# STM32H523 register map
File version: 1.3
CPU: CM33 r0p0, little endian, MPU, FPU, 4 interrupt priority bits
Registers are 32-bit, read-write, reset 0x0 unless marked. A register's access mark holds for its fields unless they carry their own. Offsets are from the block's base; [hi:lo] are bit positions; lines under a group give offsets from that group; {n}, {i} and the like mark numbered series; 'fields as' and 'values as' point back to an identical list.

## GPDMA1 — GPDMA register block
Base 0x40020000
Same registers: GPDMA2 0x40021000, GPDMA1_S 0x50020000, GPDMA2_S 0x50021000
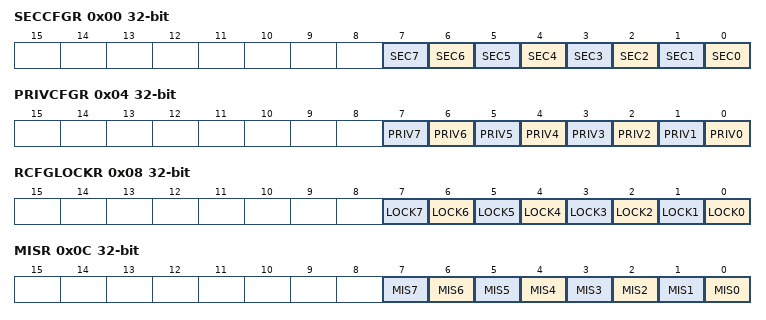
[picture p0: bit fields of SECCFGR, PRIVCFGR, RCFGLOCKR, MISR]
0x00 SECCFGR — GPDMA secure configuration register
  [n] SEC{n} (n=0..7) — secure state of channel x
0x04 PRIVCFGR — GPDMA privileged configuration register
  [n] PRIV{n} (n=0..7) — privileged state of channel x
    0=Unprivileged (Channel is unprivileged); 1=Privileged (Channel is privileged)
0x08 RCFGLOCKR — GPDMA configuration lock register
  [n] LOCK{n} (n=0..7) — lock the configuration of GPDMA_SECCFGR.
0x0C MISR ro — GPDMA nonsecure masked interrupt status register
  [n] MIS{n} (n=0..7) — masked interrupt status of channel x
    0=NoTrigger (No interrupt has occurred on channel); 1=Trigger (An interrupt has occurred on channel)
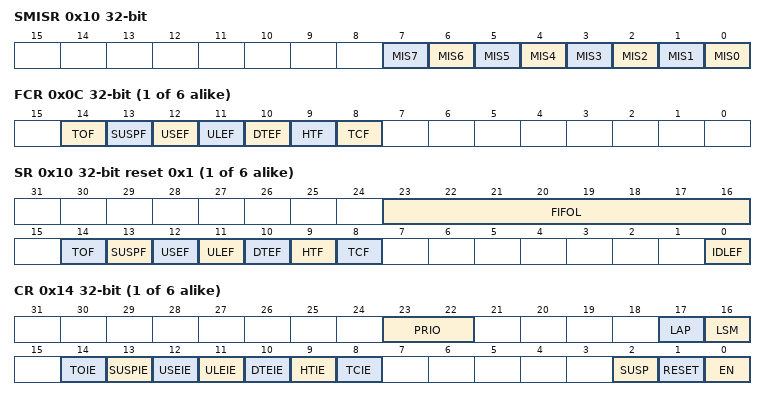
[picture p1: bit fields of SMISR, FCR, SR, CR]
0x10 SMISR ro — GPDMA secure masked interrupt status register
  [n] MIS{n} (n=0..7) — masked interrupt status of the secure channel x
{0x50+0x80*i} CH{i} (i=0..5) group — Channel cluster
  0x00 LBAR — GPDMA channel 0 linked-list base address register
    [31:16] LBA — linked-list base address of GPDMA channel x
  0x0C FCR wo — GPDMA channel 0 flag clear register
    [all] fields
      1=Clear flag
    [14] TOF — trigger overrun flag clear
    [13] SUSPF — completed suspension flag clear
    [12] USEF — user setting error flag clear
    [11] ULEF — update link transfer error flag clear
    [10] DTEF — data transfer error flag clear
    [9] HTF — half transfer flag clear
    [8] TCF — transfer complete flag clear
  0x10 SR ro reset 0x1 — GPDMA channel 0 status register
    [23:16] FIFOL — monitored FIFO level
    [14] TOF — trigger overrun flag
      0=NoTrigger (Event not triggered); 1=Trigger (Event triggered)
    [13] SUSPF — completed suspension flag
      values as TOF
    [12] USEF — user setting error flag
      values as TOF
    [11] ULEF — update link transfer error flag
      values as TOF
    [10] DTEF — data transfer error flag
      values as TOF
    [9] HTF — half transfer flag
      values as TOF
    [8] TCF — transfer complete flag
      values as TOF
    [0] IDLEF — idle flag
      values as TOF
  0x14 CR — GPDMA channel 0 control register
    [23:22] PRIO — priority level of the channel x GPDMA transfer versus others
      0=LowPrioLowWeight (Low priority, low weight); 1=LowPrioMidWeight (Low priority, mid weight); 2=LowPrioHighWeight (Low priority, high weight); 3=High priority
    [17] LAP — linked-list allocated port
      0=Port 0 (AHB) allocated; 1=Port 1 (AHB) allocated
    [16] LSM — Link step mode
      0=FullLinkedList (Channel executed for full linked list); 1=Once (Channel executed once for current linked list)
    [14] TOIE — trigger overrun interrupt enable
      0=Disabled (Interrupt disabled); 1=Enabled (Interrupt enabled)
    [13] SUSPIE — completed suspension interrupt enable
      values as TOIE
    [12] USEIE — user setting error interrupt enable
      values as TOIE
    [11] ULEIE — update link transfer error interrupt enable
      values as TOIE
    [10] DTEIE — data transfer error interrupt enable
      values as TOIE
    [9] HTIE — half transfer complete interrupt enable
      values as TOIE
    [8] TCIE — transfer complete interrupt enable
      values as TOIE
    [2] SUSP — suspend
      0=NotSuspended (Channel operation not suspended); 1=Suspended (Channel operation suspended)
    [1] RESET wo
      1=Reset channel
    [0] EN — enable
      0=Disabled (Channel disabled); 1=Enabled (Channel enabled)
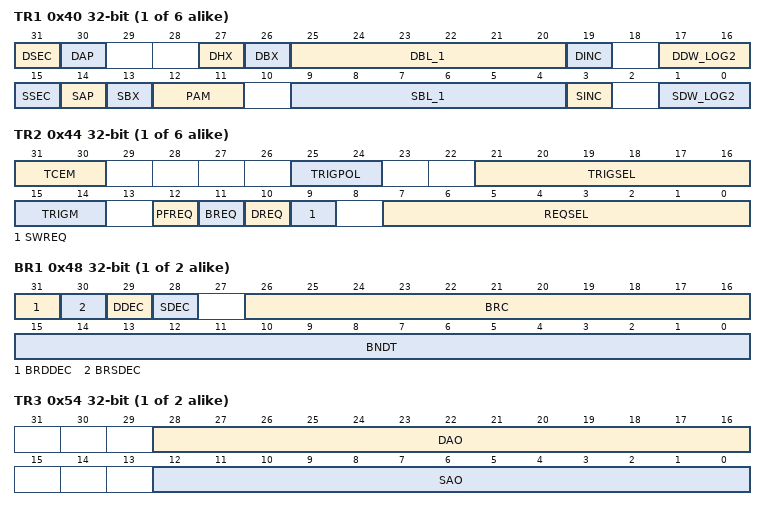
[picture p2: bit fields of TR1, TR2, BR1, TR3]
  0x40 TR1 — GPDMA channel 0 transfer register 1
    [31] DSEC — security attribute of the GPDMA transfer to the destination
    [30] DAP — destination allocated port
      0=Port 0 (AHB) allocated; 1=Port 1 (AHB) allocated
    [27] DHX — destination half-word exchange
      0=NotExchanged (No halfword-based exchange within word); 1=Exchanged (The two consecutive (post PAM) half-words are exchanged in each destination word)
    [26] DBX — destination byte exchange
      0=NotExchanged (No byte-based exchanged within word); 1=Exchanged (The two consecutive (post PAM) bytes are exchanged in each destination half-word)
    [25:20] DBL_1 — destination burst length minus 1, between 0 and 63
    [19] DINC — destination incrementing burst
      0=FixedBurst; 1=Contiguously incremented burst
    [17:16] DDW_LOG2 — binary logarithm of the destination data width of a burst, in bytes
      on read: 0=Byte; 1=Half-word (2 bytes); 2=Word (4 bytes); 3=Error (User setting error) | on write: 0=Byte; 1=Half-word (2 bytes); 2=Word (4 bytes)
    [15] SSEC — security attribute of the GPDMA transfer from the source
    [14] SAP — source allocated port
      0=Port 0 (AHB) allocated; 1=Port 1 (AHB) allocated
    [13] SBX — source byte exchange within the unaligned half-word of each source word
      values as DBX
    [12:11] PAM — padding/alignment mode
    [9:4] SBL_1 — source burst length minus 1, between 0 and 63
    [3] SINC — source incrementing burst
      0=FixedBurst; 1=Contiguously incremented burst
    [1:0] SDW_LOG2 — binary logarithm of the source data width of a burst in bytes
      values as DDW_LOG2
  0x44 TR2 — GPDMA channel 0 transfer register 2
    [31:30] TCEM — transfer complete event mode
      0=BlockLevel (At block level: the complete (and the half) transfer event is generated at the (respectively half of the) end of a block); 2=LliLevel (At LLI level: the complete transfer event is generated at the end of the LLI transfer. The half transfer event is generated at the half of the LLI data transfer); 3=ChannelLevel (At channel level: the complete transfer event is generated at the end of the last LLI transfer. The half transfer event is generated at the half of the data transfer of the last LLI)
    [25:24] TRIGPOL — trigger event polarity
      0=NoTrigger; 1=RisingEdge (Trigger on rising edge); 2=FallingEdge (Trigger on falling edge)
    [21:16] TRIGSEL — trigger event input selection
      {v}=EXTI{v} (exti{v} is trigger input) (v=0..7); 8=TAMP_TRG1 (tamp_trg1 is trigger input); 9=TAMP_TRG2 (tamp_trg2 is trigger input); 11=LPTIM1_CH1 (lptim1_ch1 is trigger input); 12=LPTIM1_CH2 (lptim1_ch2 is trigger input); 13=LPTIM2_CH1 (lptim2_ch1 is trigger input); 14=LPTIM2_CH2 (lptim2_ch2 is trigger input); 15=RTC_ALRA_TRG (rtc_alra_trg is trigger input); 16=RTC_ALRB_TRG (rtc_alrb_trg is trigger input); 17=RTC_WUT_TRG (rtc_wut_trg is trigger input); {v}=GPDMA1_CH{v-18}_TC (gpdma1_ch{v-18}_tc is trigger input) (v=18..25); {v}=GPDMA2_CH{v-26}_TC (gpdma2_ch{v-26}_tc is trigger input) (v=26..33); 34=TIM2_TRG0 (tim2_trgo is trigger input); 44=COMP1_OUT (comp1_out is trigger input)
    [15:14] TRIGM — trigger mode
      0=BlockLevel (At block level: the first burst read of each block transfer is conditioned by one hit trigger); 2=LinkLevel (At link level: a LLI link transfer is conditioned by one hit trigger); 3=ProgrammedBurstLevel (At programmed burst level: programmed burst read is conditioned by one hit trigger.)
    [12] PFREQ — Hardware request in peripheral flow control mode
      0=GpdmaControlMode (The selected hardware request is driven by a peripheral with a hardware request/acknowledge protocol in GPDMA control mode); 1=PeripheralControlMode (The selected hardware request is driven by a peripheral with a hardware request/acknowledge protocol in peripheral control mode.)
    [11] BREQ — Block hardware request
      0=Burst (The selected hardware request is driven by a peripheral with a hardware request/acknowledge protocol at a burst level); 1=Block (The selected hardware request is driven by a peripheral with a hardware request/acknowledge protocol at a block level)
    [10] DREQ — destination hardware request
      0=Source (Selected hardware request driven by a source peripheral); 1=Destination (Selected hardware request driven by a destination peripheral)
    [9] SWREQ — software request
      0=Hardware (No software request. The selected hardware request REQSEL[7:0] is taken into account); 1=Software request for memory-to-memory transfer
    [7:0] REQSEL — GPDMA hardware request selection
      0=ADC1_DMA (adc1_dma selected); 2=DAC1_CH1_DMA (dac1_ch1_dma selected); 3=DAC1_CH2_DMA (dac1_ch2_dma selected); 4=TIM6_UPD_DMA (tim6_upd_dma selected); 5=TIM7_UPD_DMA (tim7_upd_dma selected); 6=SPI1_RX_DMA (spi1_rx_dma selected); 7=SPI1_TX_DMA (spi1_tx_dma selected); 8=SPI2_RX_DMA (spi2_rx_dma selected); 9=SPI2_TX_DMA (spi2_tx_dma selected); 10=SPI3_RX_DMA (spi3_rx_dma selected); 11=SPI3_TX_DMA (spi3_tx_dma selected); 12=I2C1_RX_DMA (i2c1_rx_dma selected); 13=I2C1_TX_DMA (i2c1_tx_dma selected); 15=I2C2_RX_DMA (i2c2_rx_dma selected); 16=I2C2_TX_DMA (i2c2_tx_dma selected); 18=I2C3_RX_DMA (i2c3_rx_dma selected); 19=I2C3_TX_DMA (i2c3_tx_dma selected); 21=USART1_RX_DMA (usart1_rx_dma selected); 22=USART1_TX_DMA (usart1_tx_dma selected); 23=USART2_RX_DMA (usart2_rx_dma selected); 24=USART2_TX_DMA (usart2_tx_dma selected); 25=USART3_RX_DMA (usart3_rx_dma selected); 26=USART3_TX_DMA (usart3_tx_dma selected); 27=UART4_RX_DMA (uart4_rx_dma selected); 28=UART4_TX_DMA (uart4_tx_dma selected); 29=UART5_RX_DMA (uart5_rx_dma selected); 30=UART5_TX_DMA (uart5_tx_dma selected); 31=USART6_RX_DMA (usart6_rx_dma selected); 32=USART6_TX_DMA (usart6_tx_dma selected); 33=UART7_RX_DMA (uart7_rx_dma selected); 34=UART7_TX_DMA (uart7_tx_dma selected); 35=UART8_RX_DMA (uart8_rx_dma selected); 36=UART8_TX_DMA (uart8_tx_dma selected); 37=UART9_RX_DMA (uart9_rx_dma selected); 38=UART9_TX_DMA (uart9_tx_dma selected); 39=UART10_RX_DMA (uart10_rx_dma selected); 40=UART10_TX_DMA (uart10_tx_dma selected); 41=UART11_RX_DMA (uart11_rx_dma selected); 42=UART11_TX_DMA (uart11_tx_dma selected); 43=UART12_RX_DMA (uart12_rx_dma selected); 44=UART12_TX_DMA (uart12_tx_dma selected); 45=LPUART1_RX_DMA (lpuart1_rx_dma selected); 46=LPUART1_TX_DMA (lpuart1_tx_dma selected); 47=SPI4_RX_DMA (spi4_rx_dma selected); 48=SPI4_TX_DMA (spi4_tx_dma selected); 49=SPI5_RX_DMA (spi5_rx_dma selected); 50=SPI5_TX_DMA (spi5_tx_dma selected); 51=SPI6_RX_DMA (spi6_rx_dma selected); 52=SPI6_TX_DMA (spi6_tx_dma selected); 53=SAI1_A_DMA (sai1_a_dma selected); 54=SAI1_B_DMA (sai1_b_dma selected); 55=SAI2_A_DMA (sai2_a_dma selected); 56=SAI2_B_DMA (sai2_b_dma selected); 57=OSPI1_DMA (ospi1_dma selected); {v}=TIM1_CC{v-57}_DMA (tim1_cc{v-57}_dma selected) (v=58..61); 62=TIM1_UPD_DMA (tim1_upd_dma selected); 63=TIM1_TRG_DMA (tim1_trg_dma selected); 64=TIM1_COM_DMA (tim1_com_dma selected); {v}=TIM8_CC{v-64}_DMA (tim8_cc{v-64}_dma selected) (v=65..68); 69=TIM8_UPD_DMA (tim8_upd_dma selected); 70=TIM8_TIG_DMA (tim8_tig_dma selected); 71=TIM8_COM_DMA (tim8_com_dma selected); {v}=TIM2_CC{v-71}_DMA (tim2_cc{v-71}_dma selected) (v=72..75); 76=TIM2_UPD_DMA (tim2_upd_dma selected); {v}=TIM3_CC{v-76}_DMA (tim3_cc{v-76}_dma selected) (v=77..80); 81=TIM3_UPD_DMA (tim3_upd_dma selected); 82=TIM3_TRG_DMA (tim3_trg_dma selected); {v}=TIM4_CC{v-82}_DMA (tim4_cc{v-82}_dma selected) (v=83..86); 87=TIM4_UPD_DMA (tim4_upd_dma selected); {v}=TIM5_CC{v-87}_DMA (tim5_cc{v-87}_dma selected) (v=88..91); 92=TIM5_UPD_DMA (tim5_upd_dma selected); 93=TIM5_TRG_DMA (tim5_trg_dma selected); 94=TIM15_CC1_DMA (tim15_cc1_dma selected); 95=TIM15_UPD_DMA (tim15_upd_dma selected); 96=TIM15_TRG_DMA (tim15_trg_dma selected); 97=TIM15_COM_DMA (tim15_com_dma selected); 98=TIM16_CC1_DMA (tim16_cc1_dma selected); 99=TIM16_UPD_DMA (tim16_upd_dma selected); 100=TIM17_CC1_DMA (tim17_cc1_dma selected); 101=TIM17_UPD_DMA (tim17_upd_dma selected); 102=LPTIM1_IC1_DMA (lptim1_ic1_dma selected); 103=LPTIM1_IC2_DMA (lptim1_ic2_dma selected); 104=LPTIM1_UE_DMA (lptim1_ue_dma selected); 105=LPTIM2_IC1_DMA (lptim2_ic1_dma selected); 106=LPTIM2_IC2_DMA (lptim2_ic2_dma selected); 107=LPTIM2_UE_DMA (lptim2_ue_dma selected); 108=DCMI_PSSI_DMA (dcmi_dma or pssi_dma(1) selected); 109=AES_OUT_DMA (aes_out_dma selected); 110=AES_IN_DMA (aes_in_dma selected); 111=HASH_IN_DMA (hash_in_dma selected); 112=UCPD1_RX_DMA (ucpd1_rx_dma selected); 113=UCPD1_TX_DMA (ucpd1_tx_dma selected); 114=CORDIC_READ_DMA (cordic_read_dma selected); 115=CORDIC_WRITE_DMA (cordic_write_dma selected); 116=FMAC_READ_DMA (fmac_read_dma selected); 117=FMAC_WRITE_DMA (fmac_write_dma selected); 118=SAES_OUT_DMA (saes_out_dma selected); 119=SAES_IN_DMA (saes_in_dma selected); 120=I3C1_RX_DMA (i3c1_rx_dma selected); 121=I3C1_TX_DMA (i3c1_tx_dma selected); 122=I3C1_TC_DMA (i3c1_tc_dma selected); 123=I3C1_RS_DMA (i3c1_rs_dma selected); 124=I2C4_RX_DMA (i2c4_rx_dma selected); 125=I2C4_TX_DMA (i2c4_tx_dma selected); 127=LPTIM3_IC1_DMA (lptim3_ic1_dma selected); 128=LPTIM3_IC2_DMA (lptim3_ic2_dma selected); 129=LPTIM3_UE_DMA (lptim3_ue_dma selected); 130=LPTIM5_IC1_DMA (lptim5_ic1_dma selected); 131=LPTIM5_IC2_DMA (lptim5_ic2_dma selected); 132=LPTIM5_UE_DMA (lptim5_ue_dma selected); 133=LPTIM6_IC1_DMA (lptim6_ic1_dma selected); 134=LPTIM6_IC2_DMA (lptim6_ic2_dma selected); 135=LPTIM6_UE_DMA (lptim6_ue_dma selected); 136=I3C2_RX (i3c2_rx selected); 137=I3C2_TX (i3c2_tx selected); 138=I3C2_TC (i3c2_tc selected); 139=I3C2_RS (i3c2_rs selected)
  0x48 BR1 — GPDMA channel 0 block register 1
    [15:0] BNDT — block number of data bytes to transfer from the source
  0x4C SAR — GPDMA channel 0 source address register
    [31:0] SA — source address
  0x50 DAR — GPDMA channel 0 destination address register
    [31:0] DA — destination address
  0x7C LLR — GPDMA channel 0 linked-list address register
    [31] UT1 — Update GPDMA_CxTR1 from memory
      0=NoUpdate (No CxTR1 update); 1=Update (CxTR1 updated from memory during link transfer)
    [30] UT2 — Update GPDMA_CxTR2 from memory
      0=NoUpdate (No CxTR2 update); 1=Update (CxTR2 updated from memory during link transfer)
    [29] UB1 — Update GPDMA_CxBR1 from memory
      0=NoUpdate (No CxBR1 update); 1=Update (CxBR1 updated from memory during link transfer)
    [28] USA — update GPDMA_CxSAR from memory
      0=NoUpdate (No CxSAR update); 1=Update (CxSAR updated from memory during link transfer)
    [27] UDA — Update GPDMA_CxDAR register from memory
      0=NoUpdate (No CxDAR update); 1=Update (CxDAR updated from memory during link transfer)
    [16] ULL — Update GPDMA_CxLLR register from memory
      0=NoUpdate (No CxLLR update); 1=Update (CxLLR updated from memory during link transfer)
    [15:2] LA — pointer (16-bit low-significant address) to the next linked-list data structure
{0x50+0x80*i} CH2D{i} (i=6..7) group — 2D-addressing channel cluster
  0x00 LBAR — GPDMA channel 6 linked-list base address register
    [31:16] LBA — linked-list base address of GPDMA channel x
  0x0C FCR wo — GPDMA channel 6 flag clear register
    fields as CH0.FCR
  0x10 SR ro reset 0x1 — GPDMA channel 6 status register
    fields as CH0.SR
  0x14 CR — GPDMA channel 6 control register
    fields as CH0.CR
  0x40 TR1 — GPDMA channel 6 transfer register 1
    fields as CH0.TR1
  0x44 TR2 — GPDMA channel 6 transfer register 2
    fields as CH0.TR2
  0x48 BR1 — GPDMA channel 6 alternate block register 1
    [31] BRDDEC — Block repeat destination address decrement
      0=Increment (Block repeat destination address incremented); 1=Decrement (Block repeat destination address decremented)
    [30] BRSDEC — Block repeat source address decrement
      0=Increment (Block repeat source address incremented); 1=Decrement (Block repeat source address decremented)
    [29] DDEC — destination address decrement
      0=Increment (Destination address incremented); 1=Decrement (Destination address decremented)
    [28] SDEC — source address decrement
      0=Increment (Source address incremented); 1=Decrement (Source address decremented)
    [26:16] BRC — Block repeat counter
    [15:0] BNDT — block number of data bytes to transfer from the source
  0x4C SAR — GPDMA channel 6 source address register
    [31:0] SA — source address
  0x50 DAR — GPDMA channel 6 destination address register
    [31:0] DA — destination address
  0x54 TR3 — GPDMA channel 6 transfer register 3
    [28:16] DAO range 0..4095 — destination address offset increment
    [12:0] SAO range 0..4095 — source address offset increment
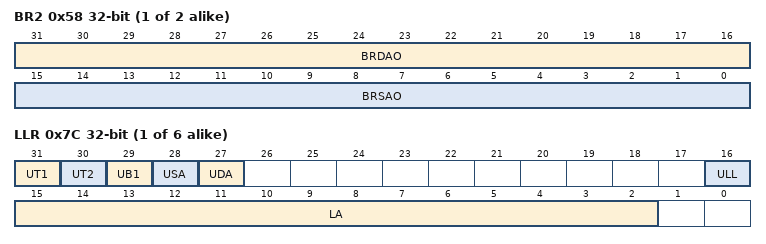
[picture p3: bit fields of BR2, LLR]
  0x58 BR2 — GPDMA channel 6 block register 2
    [31:16] BRDAO — Block repeated destination address offset
    [15:0] BRSAO — Block repeated source address offset
  0x7C LLR — GPDMA channel 6 alternate linked-list address register
    [31] UT1 — Update GPDMA_CxTR1 from memory
      values as CH0.LLR.UT1
    [30] UT2 — Update GPDMA_CxTR2 from memory
      values as CH0.LLR.UT2
    [29] UB1 — Update GPDMA_CxBR1 from memory
      values as CH0.LLR.UB1
    [28] USA — update GPDMA_CxSAR from memory
      values as CH0.LLR.USA
    [27] UDA — Update GPDMA_CxDAR register from memory
      values as CH0.LLR.UDA
    [26] UT3 — Update GPDMA_CxTR3 from memory
      0=NoUpdate (No CxTR3 update); 1=Update (CxTR3 updated from memory during link transfer)
    [25] UB2 — Update GPDMA_CxBR2 from memory
      0=NoUpdate (No CxBR2 update); 1=Update (CxBR2 updated from memory during link transfer)
    [16] ULL — Update GPDMA_CxLLR register from memory
      values as CH0.LLR.ULL
    [15:2] LA — pointer (16-bit low-significant address) to the next linked-list data structure
